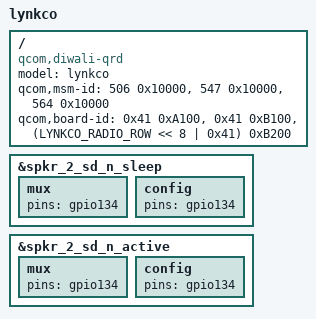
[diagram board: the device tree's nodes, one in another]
/dts-v1/;
/plugin/;

#include "diwali-audio-moto-lynkco-common.dtsi"

#define LYNKCO_RADIO_ROW 2
 / {
	model = "lynkco";
	compatible =  "qcom,diwali-qrd", "qcom,diwali", "qcom,qrd", "moto,lynkco";
	qcom,msm-id = <506 0x10000>, <547 0x10000>, <564 0x10000>;
	qcom,board-id = <0x41 0xA100>,  <0x41 0xB100>, <(LYNKCO_RADIO_ROW << 8 | 0x41) 0xB200>;
};

&spkr_2_sd_n_sleep {
	mux {
		pins = "gpio134";
	};
	config {
		pins = "gpio134";
	};
};

&spkr_2_sd_n_active {
	mux {
		pins = "gpio134";
	};
	config {
		pins = "gpio134";
	};
};
